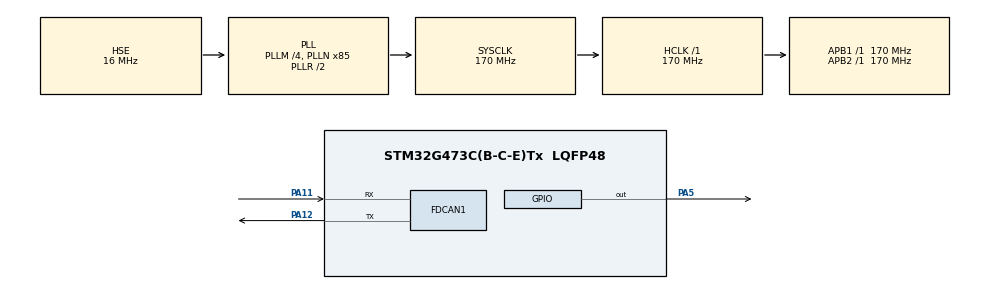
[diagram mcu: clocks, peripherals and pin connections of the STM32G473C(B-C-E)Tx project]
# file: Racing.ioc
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FDCAN1.CalculateBaudRateNominal=999999
FDCAN1.CalculateTimeBitNominal=1000
FDCAN1.CalculateTimeQuantumNominal=58.82352941176471
FDCAN1.NominalPrescaler=10
FDCAN1.NominalTimeSeg1=12
FDCAN1.NominalTimeSeg2=4
IWDG.Prescaler=IWDG_PRESCALER_64
IWDG.Reload=1000
Mcu.Family=STM32G4
Mcu.Name=STM32G473C(B-C-E)Tx
Mcu.Package=LQFP48
NVIC.PriorityGroup=NVIC_PRIORITYGROUP_4
NVIC.TIM6_DAC_IRQn=true\:0\:0\:false\:false\:true\:true\:true\:true
PA11.Mode=FDCAN_Activate
PA11.Signal=FDCAN1_RX
PA12.Mode=FDCAN_Activate
PA12.Signal=FDCAN1_TX
PA5.Signal=GPIO_Output
PF0-OSC_IN.Mode=HSE-External-Oscillator
PF0-OSC_IN.Signal=RCC_OSC_IN
PF1-OSC_OUT.Mode=HSE-External-Oscillator
PF1-OSC_OUT.Signal=RCC_OSC_OUT
ProjectManager.HeapSize=0x200
ProjectManager.StackSize=0x400
ProjectManager.TargetToolchain=STM32CubeIDE
RCC.ADC12Freq_Value=170000000
RCC.ADC345Freq_Value=170000000
RCC.AHBFreq_Value=170000000
RCC.APB1Freq_Value=170000000
RCC.APB1TimFreq_Value=170000000
RCC.APB2Freq_Value=170000000
RCC.APB2TimFreq_Value=170000000
RCC.CortexFreq_Value=170000000
RCC.EXTERNAL_CLOCK_VALUE=12288000
RCC.HCLKFreq_Value=170000000
RCC.HSE_VALUE=16000000
RCC.HSI48_VALUE=48000000
RCC.HSI_VALUE=16000000
RCC.LSE_VALUE=32768
RCC.PLLM=RCC_PLLM_DIV4
RCC.PLLN=85
RCC.PLLSourceVirtual=RCC_PLLSOURCE_HSE
RCC.SYSCLKFreq_VALUE=170000000
RCC.SYSCLKSource=RCC_SYSCLKSOURCE_PLLCLK
RCC.USBFreq_Value=170000000
RCC.VCOOutputFreq_Value=340000000
TIM6.PeriodNoDither=999
TIM6.Prescaler=16999
VP_IWDG_VS_IWDG.Mode=IWDG_Activate
VP_SYS_VS_DBSignals.Mode=DisableDeadBatterySignals
VP_TIM6_VS_ClockSourceINT.Mode=Enable_Timer
board=custom

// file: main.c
/* USER CODE BEGIN Header */
/**
  ******************************************************************************
  * @file           : main.c
  * @brief          : Main program body
  ******************************************************************************
  * @attention
  *
  * Copyright (c) 2026 STMicroelectronics.
  * All rights reserved.
  *
  * This software is licensed under terms that can be found in the LICENSE file
  * in the root directory of this software component.
  * If no LICENSE file comes with this software, it is provided AS-IS.
  *
  ******************************************************************************
  */
/* USER CODE END Header */
#include "main.h"

FDCAN_HandleTypeDef hfdcan1;

IWDG_HandleTypeDef hiwdg;

TIM_HandleTypeDef htim6;

/* USER CODE BEGIN PV */
FDCAN_TxHeaderTypeDef TxHeader;        // nagłówek ramki CAN
volatile uint8_t send_flag = 0;        // ustawiana co 1 s w przerwaniu TIM6
static uint8_t tick_cnt = 0;           // licznik przerwań (1 przerwanie = 100 ms)

/* USER CODE END PV */

void SystemClock_Config(void);
static void MX_GPIO_Init(void);
static void MX_TIM6_Init(void);
static void MX_IWDG_Init(void);
static void MX_FDCAN1_Init(void);

int main(void)
{

  /* MCU Configuration--------------------------------------------------------*/

  /* Reset of all peripherals, Initializes the Flash interface and the Systick. */
  HAL_Init();

  /* Configure the system clock */
  SystemClock_Config();

  /* Initialize all configured peripherals */
  MX_GPIO_Init();
  MX_TIM6_Init();
  MX_IWDG_Init();
  MX_FDCAN1_Init();
  /* USER CODE BEGIN 2 */
  TxHeader.Identifier          = 0x738;              // ID ramki
  TxHeader.IdType              = FDCAN_STANDARD_ID;  // 11-bitowy identyfikator
  TxHeader.TxFrameType         = FDCAN_DATA_FRAME;   // ramka z danymi
  TxHeader.DataLength          = FDCAN_DLC_BYTES_2;  // 2 bajty danych
  TxHeader.ErrorStateIndicator = FDCAN_ESI_ACTIVE;
  TxHeader.BitRateSwitch       = FDCAN_BRS_OFF;      // bez przyspieszania (Classic)
  TxHeader.FDFormat            = FDCAN_CLASSIC_CAN;  // klasyczny CAN
  TxHeader.TxEventFifoControl  = FDCAN_NO_TX_EVENTS;
  TxHeader.MessageMarker       = 0;

  if (HAL_FDCAN_Start(&hfdcan1) != HAL_OK)           // uruchomienie kontrolera CAN
  {
    Error_Handler();
  }
  HAL_TIM_Base_Start_IT(&htim6);   // TIM6 z przerwaniem co 100 ms
  /* USER CODE END 2 */

  /* Infinite loop */
  while (1)
  {

    /* USER CODE BEGIN 3 */
	  if (send_flag)
	  {
	    send_flag = 0;

	    uint16_t uptime = (uint16_t)(HAL_GetTick() / 1000);   // czas pracy w sekundach
	    uint8_t data[2];
	    data[0] = (uint8_t)(uptime >> 8);                     // starszy bajt
	    data[1] = (uint8_t)(uptime & 0xFF);                   // młodszy bajt

	    HAL_FDCAN_AddMessageToTxFifoQ(&hfdcan1, &TxHeader, data);  // wstaw ramkę do kolejki
	  }

	  HAL_IWDG_Refresh(&hiwdg);                               // odświeżenie watchdoga
  }
  /* USER CODE END 3 */
}

void SystemClock_Config(void)
{
  RCC_OscInitTypeDef RCC_OscInitStruct = {0};
  RCC_ClkInitTypeDef RCC_ClkInitStruct = {0};

  /** Configure the main internal regulator output voltage
  */
  HAL_PWREx_ControlVoltageScaling(PWR_REGULATOR_VOLTAGE_SCALE1_BOOST);

  /** Initializes the RCC Oscillators according to the specified parameters
  * in the RCC_OscInitTypeDef structure.
  */
  RCC_OscInitStruct.OscillatorType = RCC_OSCILLATORTYPE_LSI|RCC_OSCILLATORTYPE_HSE;
  RCC_OscInitStruct.HSEState = RCC_HSE_ON;
  RCC_OscInitStruct.LSIState = RCC_LSI_ON;
  RCC_OscInitStruct.PLL.PLLState = RCC_PLL_ON;
  RCC_OscInitStruct.PLL.PLLSource = RCC_PLLSOURCE_HSE;
  RCC_OscInitStruct.PLL.PLLM = RCC_PLLM_DIV4;
  RCC_OscInitStruct.PLL.PLLN = 85;
  RCC_OscInitStruct.PLL.PLLP = RCC_PLLP_DIV2;
  RCC_OscInitStruct.PLL.PLLQ = RCC_PLLQ_DIV2;
  RCC_OscInitStruct.PLL.PLLR = RCC_PLLR_DIV2;
  if (HAL_RCC_OscConfig(&RCC_OscInitStruct) != HAL_OK)
  {
    Error_Handler();
  }

  /** Initializes the CPU, AHB and APB buses clocks
  */
  RCC_ClkInitStruct.ClockType = RCC_CLOCKTYPE_HCLK|RCC_CLOCKTYPE_SYSCLK
                              |RCC_CLOCKTYPE_PCLK1|RCC_CLOCKTYPE_PCLK2;
  RCC_ClkInitStruct.SYSCLKSource = RCC_SYSCLKSOURCE_PLLCLK;
  RCC_ClkInitStruct.AHBCLKDivider = RCC_SYSCLK_DIV1;
  RCC_ClkInitStruct.APB1CLKDivider = RCC_HCLK_DIV1;
  RCC_ClkInitStruct.APB2CLKDivider = RCC_HCLK_DIV1;

  if (HAL_RCC_ClockConfig(&RCC_ClkInitStruct, FLASH_LATENCY_4) != HAL_OK)
  {
    Error_Handler();
  	  	  }
	 }

static void MX_FDCAN1_Init(void)
{

  hfdcan1.Instance = FDCAN1;
  hfdcan1.Init.ClockDivider = FDCAN_CLOCK_DIV1;
  hfdcan1.Init.FrameFormat = FDCAN_FRAME_CLASSIC;
  hfdcan1.Init.Mode = FDCAN_MODE_NORMAL;
  hfdcan1.Init.AutoRetransmission = DISABLE;
  hfdcan1.Init.TransmitPause = DISABLE;
  hfdcan1.Init.ProtocolException = DISABLE;
  hfdcan1.Init.NominalPrescaler = 10;
  hfdcan1.Init.NominalSyncJumpWidth = 1;
  hfdcan1.Init.NominalTimeSeg1 = 12;
  hfdcan1.Init.NominalTimeSeg2 = 4;
  hfdcan1.Init.DataPrescaler = 1;
  hfdcan1.Init.DataSyncJumpWidth = 1;
  hfdcan1.Init.DataTimeSeg1 = 1;
  hfdcan1.Init.DataTimeSeg2 = 1;
  hfdcan1.Init.StdFiltersNbr = 0;
  hfdcan1.Init.ExtFiltersNbr = 0;
  hfdcan1.Init.TxFifoQueueMode = FDCAN_TX_FIFO_OPERATION;
  if (HAL_FDCAN_Init(&hfdcan1) != HAL_OK)
  {
    Error_Handler();
  }

}

static void MX_IWDG_Init(void)
{

  hiwdg.Instance = IWDG;
  hiwdg.Init.Prescaler = IWDG_PRESCALER_64;
  hiwdg.Init.Window = 4095;
  hiwdg.Init.Reload = 1000;
  if (HAL_IWDG_Init(&hiwdg) != HAL_OK)
  {
    Error_Handler();
  }

}

static void MX_TIM6_Init(void)
{

  TIM_MasterConfigTypeDef sMasterConfig = {0};

  htim6.Instance = TIM6;
  htim6.Init.Prescaler = 16999;
  htim6.Init.CounterMode = TIM_COUNTERMODE_UP;
  htim6.Init.Period = 999;
  htim6.Init.AutoReloadPreload = TIM_AUTORELOAD_PRELOAD_DISABLE;
  if (HAL_TIM_Base_Init(&htim6) != HAL_OK)
  {
    Error_Handler();
  }
  sMasterConfig.MasterOutputTrigger = TIM_TRGO_RESET;
  sMasterConfig.MasterSlaveMode = TIM_MASTERSLAVEMODE_DISABLE;
  if (HAL_TIMEx_MasterConfigSynchronization(&htim6, &sMasterConfig) != HAL_OK)
  {
    Error_Handler();
  }

}

static void MX_GPIO_Init(void)
{
  GPIO_InitTypeDef GPIO_InitStruct = {0};

  /* GPIO Ports Clock Enable */
  __HAL_RCC_GPIOF_CLK_ENABLE();
  __HAL_RCC_GPIOA_CLK_ENABLE();

  /*Configure GPIO pin Output Level */
  HAL_GPIO_WritePin(GPIOA, GPIO_PIN_5, GPIO_PIN_RESET);

  /*Configure GPIO pin : PA5 */
  GPIO_InitStruct.Pin = GPIO_PIN_5;
  GPIO_InitStruct.Mode = GPIO_MODE_OUTPUT_PP;
  GPIO_InitStruct.Pull = GPIO_NOPULL;
  GPIO_InitStruct.Speed = GPIO_SPEED_FREQ_LOW;
  HAL_GPIO_Init(GPIOA, &GPIO_InitStruct);

}

/* USER CODE BEGIN 4 */

void HAL_TIM_PeriodElapsedCallback(TIM_HandleTypeDef *htim)
{
  if (htim->Instance == TIM6)                  // przerwanie od TIM6 co 100 ms
  {
    HAL_GPIO_TogglePin(GPIOA, GPIO_PIN_5);     // zmiana stanu diody -> miganie 5 Hz

    tick_cnt++;
    if (tick_cnt >= 10)                        // 10 x 100 ms = 1 s
    {
      tick_cnt = 0;
      send_flag = 1;                           // sygnał dla pętli głównej: wyślij ramkę
    }
  }
}
/* USER CODE END 4 */

void Error_Handler(void)
{
  __disable_irq();
  while (1)
  {
  }
}
